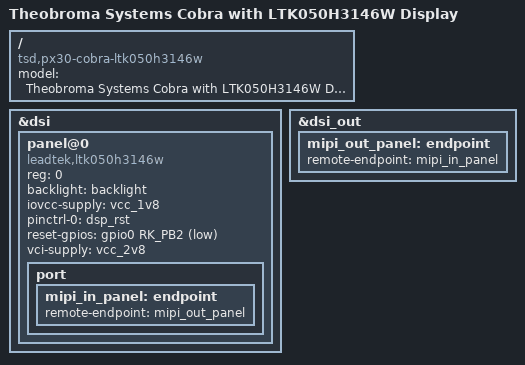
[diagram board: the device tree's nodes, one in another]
// SPDX-License-Identifier: (GPL-2.0+ OR MIT)
/*
 * Copyright (c) 2025 Cherry Embedded Solutions GmbH
 */

/dts-v1/;
#include "px30-cobra.dtsi"

/ {
	model = "Theobroma Systems Cobra with LTK050H3146W Display";
	compatible = "tsd,px30-cobra-ltk050h3146w", "tsd,px30-cobra", "rockchip,px30";
};

&dsi {
	#address-cells = <1>;
	#size-cells = <0>;
	status = "okay";

	panel@0 {
		compatible = "leadtek,ltk050h3146w";
		reg = <0>;
		backlight = <&backlight>;
		iovcc-supply = <&vcc_1v8>;
		pinctrl-names = "default";
		pinctrl-0 = <&dsp_rst>;
		reset-gpios = <&gpio0 RK_PB2 GPIO_ACTIVE_LOW>;
		vci-supply = <&vcc_2v8>;

		port {
			mipi_in_panel: endpoint {
				remote-endpoint = <&mipi_out_panel>;
			};
		};
	};
};

&dsi_out {
	mipi_out_panel: endpoint {
		remote-endpoint = <&mipi_in_panel>;
	};
};
